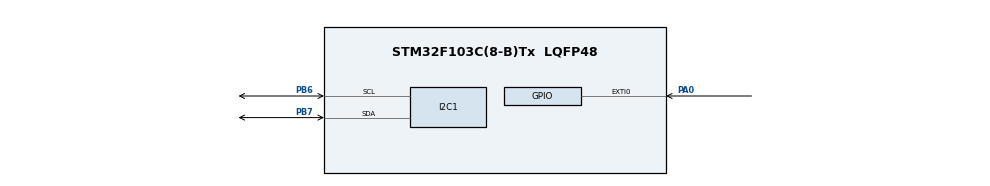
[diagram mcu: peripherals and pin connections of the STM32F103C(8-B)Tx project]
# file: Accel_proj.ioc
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Mcu.Family=STM32F1
Mcu.Name=STM32F103C(8-B)Tx
Mcu.Package=LQFP48
NVIC.EXTI0_IRQn=true\:1\:0\:true\:false\:true\:true\:true\:true
NVIC.PriorityGroup=NVIC_PRIORITYGROUP_4
PA0-WKUP.GPIO_ModeDefaultEXTI=GPIO_MODE_IT_RISING
PA0-WKUP.GPIO_PuPd=GPIO_PULLDOWN
PA0-WKUP.Signal=GPXTI0
PA13.Mode=Serial_Wire
PA13.Signal=SYS_JTMS-SWDIO
PA14.Mode=Serial_Wire
PA14.Signal=SYS_JTCK-SWCLK
PB6.Mode=I2C
PB6.Signal=I2C1_SCL
PB7.Mode=I2C
PB7.Signal=I2C1_SDA
PD0-OSC_IN.Mode=HSE-External-Oscillator
PD0-OSC_IN.Signal=RCC_OSC_IN
PD1-OSC_OUT.Mode=HSE-External-Oscillator
PD1-OSC_OUT.Signal=RCC_OSC_OUT
ProjectManager.HeapSize=0x200
ProjectManager.StackSize=0x400
ProjectManager.TargetToolchain=EWARM V8.32
RCC.APB1Freq_Value=8000000
RCC.APB2Freq_Value=8000000
RCC.SYSCLKSource=RCC_SYSCLKSOURCE_HSE
board=custom

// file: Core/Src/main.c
/* USER CODE BEGIN Header */
/**
  ******************************************************************************
  * @file           : main.c
  * @brief          : Main program body
  ******************************************************************************
  * @attention
  *
  * Copyright (c) 2026 STMicroelectronics.
  * All rights reserved.
  *
  * This software is licensed under terms that can be found in the LICENSE file
  * in the root directory of this software component.
  * If no LICENSE file comes with this software, it is provided AS-IS.
  *
  ******************************************************************************
  */
/* USER CODE END Header */
#include "main.h"

/* USER CODE BEGIN Includes */
#include "MPU6050\MPU6050.h"
#include "SSD1306\ssd1306.h"
#include "SSD1306\ssd1306_fonts.h"
#include <stdio.h>
#include <math.h>
/* USER CODE END Includes */

I2C_HandleTypeDef hi2c1;

/* USER CODE BEGIN PV */
#define MAX_PIXEL_OFFSET    25

MPU6050_Data_t mpu_data;
char buffer1[30];
const float ANGLE_TO_PIXEL_SCALE = 0.75f;
const float alpha = 0.4f;
static float filtered_roll = 0.0f;
static float filtered_pitch = 0.0f;

/* USER CODE END PV */

void SystemClock_Config(void);
static void MX_GPIO_Init(void);
static void MX_I2C1_Init(void);

int main(void)
{

  /* MCU Configuration--------------------------------------------------------*/

  /* Reset of all peripherals, Initializes the Flash interface and the Systick. */
  HAL_Init();

  /* Configure the system clock */
  SystemClock_Config();

  /* Initialize all configured peripherals */
  MX_GPIO_Init();
  MX_I2C1_Init();

  /* Infinite loop */
  /* USER CODE BEGIN WHILE */
  ssd1306_Init();
  ssd1306_Fill(Black);
  ssd1306_UpdateScreen();

  MPU6050_Init(&hi2c1);

  MPU6050_Calibrate(&hi2c1);

  while (1)
  {
    if(MPU6050_Read_Accel(&hi2c1, &mpu_data)==HAL_OK)
    {
     ssd1306_Fill(Black);
     filtered_roll = (alpha * mpu_data.roll) + ((1.0f - alpha) * filtered_roll);
     filtered_pitch = (alpha * mpu_data.pitch) + ((1.0f - alpha) * filtered_pitch);

     float offsetX =  filtered_roll * ANGLE_TO_PIXEL_SCALE;
     float offsetY = -1* filtered_pitch * ANGLE_TO_PIXEL_SCALE;

     float current_distance = sqrtf(offsetX * offsetX + offsetY * offsetY);
     if (current_distance > MAX_PIXEL_OFFSET )
     {
       float scale = MAX_PIXEL_OFFSET / current_distance;
       offsetX =offsetX * scale;
       offsetY =offsetY * scale;
     }

    ssd1306_DrawCircle(64, 32, 30, White);
    ssd1306_FillCircle(64 +(int)offsetX,32 +(int)offsetY,4,White);

//    sprintf(buffer1, "R:%.1f P:%.1f", mpu_data.roll, mpu_data.pitch);
//    ssd1306_SetCursor(0, 0);
//    ssd1306_WriteString(buffer1, Font_7x10, White);
//    ssd1306_UpdateScreen();

    HAL_Delay(20);}
    /* USER CODE END WHILE */

  }
}

void SystemClock_Config(void)
{
  RCC_OscInitTypeDef RCC_OscInitStruct = {0};
  RCC_ClkInitTypeDef RCC_ClkInitStruct = {0};

  /** Initializes the RCC Oscillators according to the specified parameters
  * in the RCC_OscInitTypeDef structure.
  */
  RCC_OscInitStruct.OscillatorType = RCC_OSCILLATORTYPE_HSE;
  RCC_OscInitStruct.HSEState = RCC_HSE_ON;
  RCC_OscInitStruct.PLL.PLLState = RCC_PLL_NONE;
  if (HAL_RCC_OscConfig(&RCC_OscInitStruct) != HAL_OK)
  {
    Error_Handler();
  }

  /** Initializes the CPU, AHB and APB buses clocks
  */
  RCC_ClkInitStruct.ClockType = RCC_CLOCKTYPE_HCLK|RCC_CLOCKTYPE_SYSCLK
                              |RCC_CLOCKTYPE_PCLK1|RCC_CLOCKTYPE_PCLK2;
  RCC_ClkInitStruct.SYSCLKSource = RCC_SYSCLKSOURCE_HSE;
  RCC_ClkInitStruct.AHBCLKDivider = RCC_SYSCLK_DIV1;
  RCC_ClkInitStruct.APB1CLKDivider = RCC_HCLK_DIV1;
  RCC_ClkInitStruct.APB2CLKDivider = RCC_HCLK_DIV1;

  if (HAL_RCC_ClockConfig(&RCC_ClkInitStruct, FLASH_LATENCY_0) != HAL_OK)
  {
    Error_Handler();
  }
}

static void MX_I2C1_Init(void)
{

  hi2c1.Instance = I2C1;
  hi2c1.Init.ClockSpeed = 100000;
  hi2c1.Init.DutyCycle = I2C_DUTYCYCLE_2;
  hi2c1.Init.OwnAddress1 = 0;
  hi2c1.Init.AddressingMode = I2C_ADDRESSINGMODE_7BIT;
  hi2c1.Init.DualAddressMode = I2C_DUALADDRESS_DISABLE;
  hi2c1.Init.OwnAddress2 = 0;
  hi2c1.Init.GeneralCallMode = I2C_GENERALCALL_DISABLE;
  hi2c1.Init.NoStretchMode = I2C_NOSTRETCH_DISABLE;
  if (HAL_I2C_Init(&hi2c1) != HAL_OK)
  {
    Error_Handler();
  }

}

static void MX_GPIO_Init(void)
{
  GPIO_InitTypeDef GPIO_InitStruct = {0};

  /* GPIO Ports Clock Enable */
  __HAL_RCC_GPIOD_CLK_ENABLE();
  __HAL_RCC_GPIOA_CLK_ENABLE();
  __HAL_RCC_GPIOB_CLK_ENABLE();

  /*Configure GPIO pin : PA0 */
  GPIO_InitStruct.Pin = GPIO_PIN_0;
  GPIO_InitStruct.Mode = GPIO_MODE_IT_RISING;
  GPIO_InitStruct.Pull = GPIO_PULLDOWN;
  HAL_GPIO_Init(GPIOA, &GPIO_InitStruct);

  /* EXTI interrupt init*/
  HAL_NVIC_SetPriority(EXTI0_IRQn, 1, 0);
  HAL_NVIC_EnableIRQ(EXTI0_IRQn);

}

void Error_Handler(void)
{
  __disable_irq();
  while (1)
  {
  }
}
